# nrf52833 register map
Vendor: Nordic Semiconductor; Series: nrf52; File version: 1
CPU: CM4 r0p1, little endian, MPU, FPU, 3 interrupt priority bits
Registers are 32-bit, read-write, reset 0x0 unless marked. A register's access mark holds for its fields unless they carry their own. Offsets are from the block's base; [hi:lo] are bit positions; lines under a group give offsets from that group; 'fields as' and 'values as' point back to an identical list.

## UART0 — Universal Asynchronous Receiver/Transmitter
Base 0x40002000
0x00 TASKS_STARTRX wo — Start UART receiver
  [0] TASKS_STARTRX
    1=Trigger task
0x04 TASKS_STOPRX wo — Stop UART receiver
  [0] TASKS_STOPRX
    1=Trigger task
0x08 TASKS_STARTTX wo — Start UART transmitter
  [0] TASKS_STARTTX
    1=Trigger task
0x0C TASKS_STOPTX wo — Stop UART transmitter
  [0] TASKS_STOPTX
    1=Trigger task
0x1C TASKS_SUSPEND wo — Suspend UART
  [0] TASKS_SUSPEND
    1=Trigger task
0x100 EVENTS_CTS — CTS is activated (set low). Clear To Send.
  [0] EVENTS_CTS
    0=NotGenerated (Event not generated); 1=Generated (Event generated)
0x104 EVENTS_NCTS — CTS is deactivated (set high). Not Clear To Send.
  [0] EVENTS_NCTS
    values as EVENTS_CTS.EVENTS_CTS
0x108 EVENTS_RXDRDY — Data received in RXD
  [0] EVENTS_RXDRDY
    values as EVENTS_CTS.EVENTS_CTS
0x11C EVENTS_TXDRDY — Data sent from TXD
  [0] EVENTS_TXDRDY
    values as EVENTS_CTS.EVENTS_CTS
0x124 EVENTS_ERROR — Error detected
  [0] EVENTS_ERROR
    values as EVENTS_CTS.EVENTS_CTS
0x144 EVENTS_RXTO — Receiver timeout
  [0] EVENTS_RXTO
    values as EVENTS_CTS.EVENTS_CTS
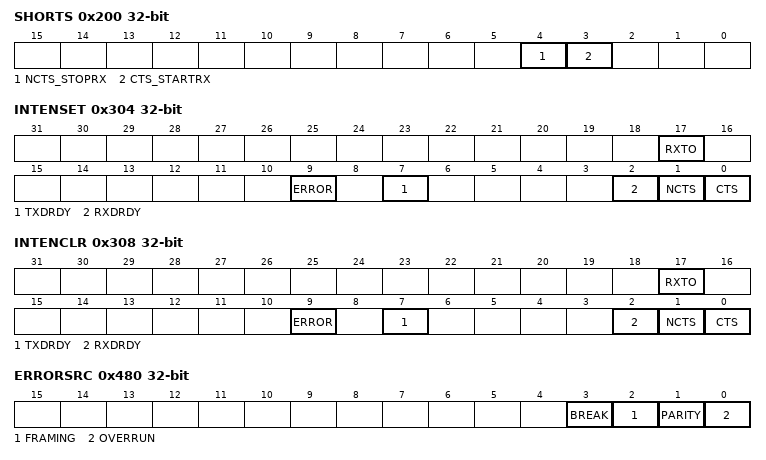
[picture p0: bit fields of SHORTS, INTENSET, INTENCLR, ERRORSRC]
0x200 SHORTS — Shortcuts between local events and tasks
  [4] NCTS_STOPRX — Shortcut between event NCTS and task STOPRX
    0=Disabled (Disable shortcut); 1=Enabled (Enable shortcut)
  [3] CTS_STARTRX — Shortcut between event CTS and task STARTRX
    0=Disabled (Disable shortcut); 1=Enabled (Enable shortcut)
0x304 INTENSET — Enable interrupt
  [all] fields
    on read: 0=Disabled (Read: Disabled); 1=Enabled (Read: Enabled) | on write: 1=Set (Enable)
  [17] RXTO — Write '1' to enable interrupt for event RXTO
  [9] ERROR — Write '1' to enable interrupt for event ERROR
  [7] TXDRDY — Write '1' to enable interrupt for event TXDRDY
  [2] RXDRDY — Write '1' to enable interrupt for event RXDRDY
  [1] NCTS — Write '1' to enable interrupt for event NCTS
  [0] CTS — Write '1' to enable interrupt for event CTS
0x308 INTENCLR — Disable interrupt
  [all] fields
    on read: 0=Disabled (Read: Disabled); 1=Enabled (Read: Enabled) | on write: 1=Clear (Disable)
  [17] RXTO — Write '1' to disable interrupt for event RXTO
  [9] ERROR — Write '1' to disable interrupt for event ERROR
  [7] TXDRDY — Write '1' to disable interrupt for event TXDRDY
  [2] RXDRDY — Write '1' to disable interrupt for event RXDRDY
  [1] NCTS — Write '1' to disable interrupt for event NCTS
  [0] CTS — Write '1' to disable interrupt for event CTS
0x480 ERRORSRC write-1-clears — Error source
  [all] fields
    on read: 0=NotPresent (Read: error not present); 1=Present (Read: error present)
  [3] BREAK — Break condition
  [2] FRAMING — Framing error occurred
  [1] PARITY — Parity error
  [0] OVERRUN — Overrun error
0x500 ENABLE — Enable UART
  [3:0] ENABLE — Enable or disable UART
    0=Disabled (Disable UART); 4=Enabled (Enable UART)
0x508 PSEL group — Unspecified
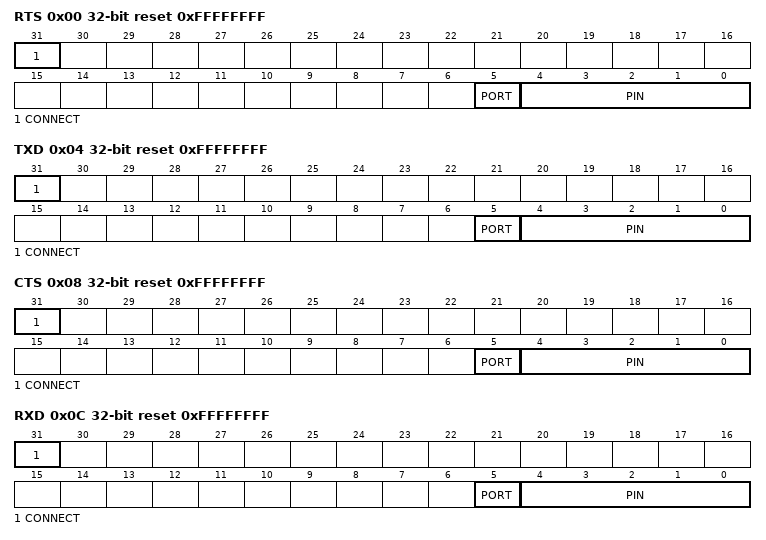
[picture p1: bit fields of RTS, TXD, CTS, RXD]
  0x00 RTS reset 0xFFFFFFFF — Pin select for RTS
    [31] CONNECT — Connection
      1=Disconnected; 0=Connected
    [5] PORT — Port number
    [4:0] PIN — Pin number
  0x04 TXD reset 0xFFFFFFFF — Pin select for TXD
    fields as PSEL.RTS
  0x08 CTS reset 0xFFFFFFFF — Pin select for CTS
    fields as PSEL.RTS
  0x0C RXD reset 0xFFFFFFFF — Pin select for RXD
    fields as PSEL.RTS
0x518 RXD ro read-has-side-effects
  [7:0] RXD — RX data received in previous transfers, double buffered
0x51C TXD wo
  [7:0] TXD — TX data to be transferred
0x524 BAUDRATE reset 0x4000000 — Baud rate. Accuracy depends on the HFCLK source selected.
  [31:0] BAUDRATE
    0x4F000=Baud1200 (1200 baud (actual rate: 1205)); 0x9D000=Baud2400 (2400 baud (actual rate: 2396)); 0x13B000=Baud4800 (4800 baud (actual rate: 4808)); 0x275000=Baud9600 (9600 baud (actual rate: 9598)); 0x3B0000=Baud14400 (14400 baud (actual rate: 14414)); 0x4EA000=Baud19200 (19200 baud (actual rate: 19208)); 0x75F000=Baud28800 (28800 baud (actual rate: 28829)); 0x800000=Baud31250 (31250 baud); 0x9D5000=Baud38400 (38400 baud (actual rate: 38462)); 0xE50000=Baud56000 (56000 baud (actual rate: 55944)); 0xEBF000=Baud57600 (57600 baud (actual rate: 57762)); 0x13A9000=Baud76800 (76800 baud (actual rate: 76923)); 0x1D7E000=Baud115200 (115200 baud (actual rate: 115942)); 0x3AFB000=Baud230400 (230400 baud (actual rate: 231884)); 0x4000000=Baud250000 (250000 baud); 0x75F7000=Baud460800 (460800 baud (actual rate: 470588)); 0xEBED000=Baud921600 (921600 baud (actual rate: 941176)); 0x10000000=Baud1M (1Mega baud)
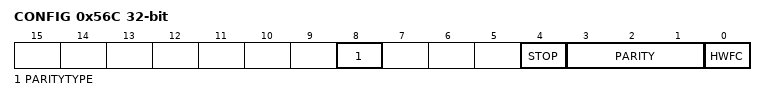
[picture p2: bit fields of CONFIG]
0x56C CONFIG — Configuration of parity and hardware flow control
  [8] PARITYTYPE — Even or odd parity type
    0=Even parity; 1=Odd (Odd parity)
  [4] STOP — Stop bits
    0=One (One stop bit); 1=Two (Two stop bits)
  [3:1] PARITY
    0=Excluded (Exclude parity bit); 7=Included (Include parity bit)
  [0] HWFC — Hardware flow control
    0=Disabled; 1=Enabled
